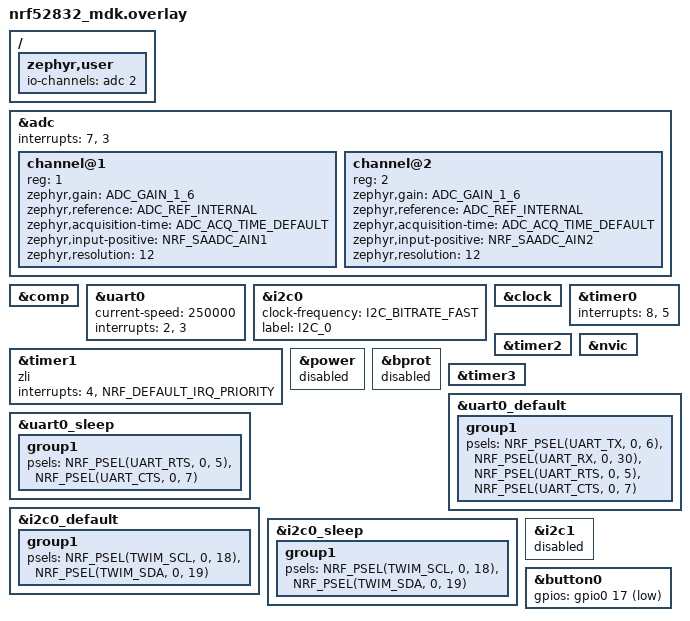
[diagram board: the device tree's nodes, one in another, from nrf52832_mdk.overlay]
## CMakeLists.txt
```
# SPDX-License-Identifier: Apache-2.0

cmake_minimum_required(VERSION 3.20.0)

find_package(Zephyr REQUIRED HINTS $ENV{ZEPHYR_BASE})
project(hello_world)

target_sources(app PRIVATE src/main.c)
target_sources(app PRIVATE src/soft_iic.c)
target_sources(app PRIVATE src/imu_bag.c)
target_sources(app PRIVATE src/timer.c)
target_sources(app PRIVATE src/adc.c)
target_sources(app PRIVATE src/iic_twi.c)
target_sources(app PRIVATE src/uart.c)
target_sources(app PRIVATE src/fft.c)
target_sources(app PRIVATE src/ble.c)
target_sources(app PRIVATE src/ads1015.c)
target_sources(app PRIVATE src/ads1220.c)
target_sources(app PRIVATE src/goertzel.c)
```

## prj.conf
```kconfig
CONFIG_USE_SEGGER_RTT=y
CONFIG_RTT_CONSOLE=y
CONFIG_LED=y
CONFIG_LOG=y
CONFIG_PWM=y
CONFIG_LOG_MODE_IMMEDIATE=y
CONFIG_I2C=y
CONFIG_I2C_NRFX=y
CONFIG_NRFX_TIMER2=y
CONFIG_NRFX_TIMER3=y
CONFIG_ADC=y
CONFIG_UART_ASYNC_API=y
CONFIG_COUNTER=y
CONFIG_DMA=y
CONFIG_SYSCON=y
CONFIG_SERIAL=y
CONFIG_UART_INTERRUPT_DRIVEN=y

CONFIG_NRFX_SAADC=y
CONFIG_NRFX_TWI0=y

CONFIG_BT=y
CONFIG_BT_BROADCASTER=y
CONFIG_BT_EXT_ADV=y
CONFIG_BT_EXT_ADV_MAX_ADV_SET=1
CONFIG_BT_DEVICE_NAME="Broadcaster Multiple"


CONFIG_BT_CTLR_ADV_DATA_LEN_MAX=1065
CONFIG_BT_HCI_VS_EVT_USER=y
CONFIG_BT_CTLR_TX_PWR_ANTENNA=-4


CONFIG_CMSIS_DSP=y
CONFIG_CMSIS_DSP_TRANSFORM=y
CONFIG_CMSIS_DSP_TABLES_ARM_COS_F32=y
CONFIG_CMSIS_DSP_TABLES_ARM_SIN_F32=y
CONFIG_CMSIS_DSP_COMPLEXMATH=y
CONFIG_LOG=y

CONFIG_MAIN_STACK_SIZE=4096


CONFIG_CMSIS_NN=y

CONFIG_CMSIS_DSP_CONTROLLER=y
CONFIG_CMSIS_DSP_FILTERING=y
CONFIG_CMSIS_DSP_INTERPOLATION=y
CONFIG_CMSIS_DSP_MATRIX=y
CONFIG_CMSIS_DSP_QUATERNIONMATH=y
CONFIG_CMSIS_DSP_SVM=y
CONFIG_CMSIS_DSP_BAYES=y
CONFIG_CMSIS_DSP_DISTANCE=y
CONFIG_CMSIS_DSP_LOOPUNROLL=y
CONFIG_CMSIS_DSP_ROUNDING=y
CONFIG_CMSIS_DSP_MATRIXCHECK=y
CONFIG_CMSIS_DSP_AUTOVECTORIZE=y

CONFIG_NRFX_SPI2=y


# # nothing here
# # Enable MCUBoot.
# CONFIG_BOOTLOADER_MCUBOOT=y

# # Enable flash operations.
# CONFIG_FLASH=y

# # Enable MCUmgr and dependencies.
# CONFIG_MCUMGR=y
# CONFIG_NET_BUF=y
# CONFIG_ZCBOR=y
# CONFIG_CRC=y
# CONFIG_STREAM_FLASH=y
# CONFIG_FLASH_MAP=y

# # Enable most core commands.
# CONFIG_IMG_MANAGER=y
# CONFIG_MCUMGR_GRP_IMG=y
# CONFIG_MCUMGR_GRP_OS=y

# # Enable the serial mcumgr transport.
# CONFIG_MCUMGR_TRANSPORT_UART=y
# CONFIG_BASE64=y
# CONFIG_CONSOLE=y

# # Disable UART Console and enable the RTT console
# CONFIG_UART_CONSOLE=n
# CONFIG_RTT_CONSOLE=y
# CONFIG_USE_SEGGER_RTT=y

# # Some command handlers require a large stack.
# CONFIG_SYSTEM_WORKQUEUE_STACK_SIZE=4096
```

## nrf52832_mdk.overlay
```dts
// To get started, press Ctrl+Space to bring up the completion menu and view the available nodes.

// You can also use the buttons in the sidebar to perform actions on nodes.
// Actions currently available include:

// * Enabling / disabling the node
// * Adding the bus to a bus
// * Removing the node
// * Connecting ADC channels

// For more help, browse the DeviceTree documentation at https://docs.zephyrproject.org/latest/guides/dts/index.html
// You can also visit the nRF DeviceTree extension documentation at https://nrfconnect.github.io/vscode-nrf-connect/devicetree/nrfdevicetree.html
/ {
	zephyr,user {
		io-channels = <&adc 2>;
	};
};
&adc {
	#address-cells = <1>;
	#size-cells = <0>;
	channel@1 {
		reg = <1>;
		zephyr,gain = "ADC_GAIN_1_6";
		zephyr,reference = "ADC_REF_INTERNAL";
		zephyr,acquisition-time = <ADC_ACQ_TIME_DEFAULT>;
		zephyr,input-positive = <NRF_SAADC_AIN1>; /* P0.03 */
		zephyr,resolution = <12>;
	};
	channel@2 {
		reg = <2>;
		zephyr,gain = "ADC_GAIN_1_6";
		zephyr,reference = "ADC_REF_INTERNAL";
		zephyr,acquisition-time = <ADC_ACQ_TIME_DEFAULT>;
		zephyr,input-positive = <NRF_SAADC_AIN2>; /* P0.04 */
		zephyr,resolution = <12>;
	};

	status = "okay";

	interrupts = <7>, <3>;
};
&comp {
	status = "okay";
};
&uart0 {
	current-speed = <250000>;
	interrupts = <2>, <3>;
};

&i2c0 {
	clock-frequency = <I2C_BITRATE_FAST>;
	label = "I2C_0";
	status = "okay";
};

&clock {
	status = "okay";
};

&timer0 {
	status = "okay";
	interrupts = <8>, <5>;
};

&timer1 {
	status = "okay";
	zli;
	interrupts = <4>, <NRF_DEFAULT_IRQ_PRIORITY>;
};

&timer2 {
	status = "okay";
};

&nvic {
	status = "okay";
};

&power {
	status = "disabled";
};

&bprot {
	status = "disabled";
};

&timer3 {
	status = "okay";
};

&uart0_default {
	group1 {
		psels = <NRF_PSEL(UART_TX, 0, 6)>,
				<NRF_PSEL(UART_RX, 0, 30)>,
				<NRF_PSEL(UART_RTS, 0, 5)>,
				<NRF_PSEL(UART_CTS, 0, 7)>;
	};
};

&uart0_sleep {
	group1 {
		psels = <NRF_PSEL(UART_RTS, 0, 5)>, <NRF_PSEL(UART_CTS, 0, 7)>;
	};
};
/delete-node/ &{/pin-controller/i2c1_default/group1/};
/delete-node/ &{/pin-controller/i2c1_sleep/group1/};
/delete-node/ &{/pin-controller/i2c0_default/group1/};
/delete-node/ &{/pin-controller/i2c0_sleep/group1/};

&i2c0_default {
	group1 {
		psels = <NRF_PSEL(TWIM_SCL, 0, 18)>, <NRF_PSEL(TWIM_SDA, 0, 19)>;
	};
};

&i2c0_sleep {
	group1 {
		psels = <NRF_PSEL(TWIM_SCL, 0, 18)>, <NRF_PSEL(TWIM_SDA, 0, 19)>;
	};
};

&i2c1 {
	status = "disabled";
};

&button0 {
	gpios = <&gpio0 17 (GPIO_ACTIVE_LOW | GPIO_PULL_UP)>;
};
```

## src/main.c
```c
// /*
//  * Copyright (c) 2012-2014 Wind River Systems, Inc.
//  *
//  * SPDX-License-Identifier: Apache-2.0
//  */
#include "imu_bag.h"
#include "timer.h"
#include "adc.h"
#include "iic_twi.h"
#include "icm_42688.h"
#include "uart.h"
#include <stdio.h>
#include "zephyr/logging/log.h"
#include "nrfx_saadc.h"
#include <zephyr/kernel.h>
#include "nrfx_twi.h"
#include "nrfx_twim.h"
#include "nrfx_gpiote.h"
#include <zephyr/irq.h>
#include "ads1015.h"
#include "ads1220.h"
#include "mymacros.h"
#include "hal/nrf_gpio.h"



//定义一个Gain control 0.31
#define GC NRF_GPIO_PIN_MAP(0, 31) 
// // 定义一个用于读取消息队列的线程堆栈空间
// #define STACK_SIZE 1024
// #define PRIORITY 5
// // 读取线程的栈空间
// K_THREAD_STACK_DEFINE(read_thread_stack, STACK_SIZE);
// // 定义一个线程数据结构
// struct k_thread read_thread_data;
extern struct k_msgq uart_msgq;
char tx_buf[MSG_SIZE];
//尝试使用消息队列
K_MSGQ_DEFINE(uart_msgq2, sizeof(char *), 5, 4); // 队列大小为10，消息长度为指针大小
K_MSGQ_DEFINE(uart_msgq3, sizeof(char *), 3, 4); // 队列大小为10，消息长度为指针大小，存储imu的数据
void get_MSGQ(void)
{
	//用于将数据获取队列并进行输出
	char *msg;
	while(k_msgq_get(&uart_msgq2,&msg,K_NO_WAIT)==0)
	{
		print_uart(msg);
	}
	//进行双消息队列的存储
	while(k_msgq_get(&uart_msgq3,&msg,K_NO_WAIT)==0)
	{
		print_uart(msg);
	}
	// //继续读取中断返回的数
	// while(k_msgq_get(&uart_msgq,&tx_buf,K_NO_WAIT)==0)
	// {
	// 	print_uart(tx_buf);
	// }
}
#define TWI_INSTANCE_ID     0
#define TWI_SCL_PIN         NRF_GPIO_PIN_MAP(0, 18)
#define TWI_SDA_PIN			NRF_GPIO_PIN_MAP(0, 19)
// #define TWI_SCL_PIN         NRF_GPIO_PIN_MAP(0, 27)
// #define TWI_SDA_PIN			NRF_GPIO_PIN_MAP(0, 26)
//定义一个发送完成的变量
bool twi_done=true;
// 定义 TWI 实例结构体
nrfx_twi_t m_twi = NRFX_TWI_INSTANCE(TWI_INSTANCE_ID);
// void twi_handler(nrfx_twi_evt_t const * p_event, void * p_context) 
// {
// 	switch (p_event->type) {
// 		case NRFX_TWI_EVT_DONE:
// 			/* Transfer completed */
// 			twi_done=true;
// 			break;
// 		case NRFX_TWI_EVT_ADDRESS_NACK:
// 			/* NACK received after sending the address */
// 			printk("address nack");
// 			break;
// 		case NRFX_TWI_EVT_DATA_NACK:
// 			/* NACK received after sending a data byte */
// 			printk("data nack");
// 			break;
// 		default:
// 			break;
// 	}
// }
// 初始化 TWI
void twi_init(void)
{
	nrfx_err_t err_code;
    // 配置 TWI
    const nrfx_twi_config_t twi_config = {
        .scl = TWI_SCL_PIN,
        .sda = TWI_SDA_PIN,
        .frequency = NRF_TWI_FREQ_400K,
        .interrupt_priority = 4,
        .hold_bus_uninit = false,
    };
    err_code = nrfx_twi_init(&m_twi, &twi_config, NULL, NULL);
	// IRQ_DIRECT_CONNECT(NRFX_IRQ_NUMBER_GET(NRF_TWI_INST_GET(0)), IRQ_PRIO_LOWEST,
    //                    NRFX_TWI_INST_HANDLER_GET(0), 0);
	// irq_enable(NRFX_IRQ_NUMBER_GET(NRF_TWI_INST_GET(0)));
	// printk("IRQ_PRIO_LOWEST:%d\n",IRQ_PRIO_LOWEST);
	// printk("NRFX_IRQ_NUMBER_GET(NRF_TWI_INST_GET(0)):%d\n",	NRFX_IRQ_NUMBER_GET(NRF_TWI_INST_GET(0)));
	// printk("BIT:%d\n",	 (_IRQ_PRIO_OFFSET));
	// printk("BIT:%d\n",	 twi_config.interrupt_priority);
    // 使能 TWI
    nrfx_twi_enable(&m_twi);
	printk("this is a twi ok");
}

//定义IIC的设备名称
// struct device *i2c_dev;
// #define I2C_DEV_NAME "I2C_0"
//用于进行flag的调用
int flag =0;
//存储一定的AD进而来进行在一定下进行输送
int pd[1000];
int pd2[1000];
//存储一定的imu进行来输送
int imu_count=0;
//用于imu的数据发送
// int count_imu =0;
// int imu_flag =0;
//这里是0.5秒的计时器
int count =1;
int b = 0;
int c = 1;
int imu_flag =0;

//以下是大的时间戳 0.5秒计时一次 0-65536
u_int16_t big_time = 0;
//MovingFlag 与beacondeviceType
uint8_t Mov_type = 0; 
//Moving flag 0为不动 1为动
uint8_t Moving_flag = 0;
//标志不同类型
uint8_t beacon_type = 0;
//标志接受端的电池容量
uint8_t voltage = 0;
//标志接收端的imu的时间戳
int small_time = 0; 

//以下是nrf库的adc采样
LOG_MODULE_REGISTER(adc, LOG_LEVEL_DBG);

#define CHANNEL_COUNT 1

static nrfx_saadc_channel_t single_channel = NRFX_SAADC_DEFAULT_CHANNEL_SE(NRF_SAADC_INPUT_AIN2, 0);
static nrf_saadc_value_t buffer[CHANNEL_COUNT];

void Bsp_HFCLK_Init_Extern()
{
    NRF_CLOCK->EVENTS_HFCLKSTARTED = 0;
    NRF_CLOCK->TASKS_HFCLKSTART = 1;

    while (NRF_CLOCK->EVENTS_HFCLKSTARTED == 0)
    {
        // Do nothing.
    }
}

int adc_init2(void)
{
	Bsp_HFCLK_Init_Extern();
	nrfx_err_t err;
	//初始化 输入初始化的中断优秀级
	err = nrfx_saadc_init(NRFX_SAADC_DEFAULT_CONFIG_IRQ_PRIORITY);
	//配置通道的属性
	single_channel.channel_config.gain = NRF_SAADC_GAIN1_4;
	//显示通道的采样时间间隔
	LOG_INF("TIME=%d\r\n",single_channel.channel_config.acq_time);
	//nrfx_saadc_channel_config完成通道的配置
	err = nrfx_saadc_channel_config(&single_channel);
	//nrfx_saadc_channels_configured_get();记录了当前配置的通道配置情况
	uint32_t channels_mask = nrfx_saadc_channels_configured_get();
	LOG_INF("ADC channels mask: %d\n", channels_mask);
	//设置通道分辨率为12bit，不使用过采样，事件回调
	err = nrfx_saadc_simple_mode_set(channels_mask, NRF_SAADC_RESOLUTION_12BIT, NRF_SAADC_OVERSAMPLE_DISABLED, NULL);
	//在开始 SAADC 转换之前，您需要调用此函数来设置一个缓冲区，SAADC 将把采样数据存储到这个缓冲区中。
	err = nrfx_saadc_buffer_set(buffer, CHANNEL_COUNT);
}

int adc_value_get(void)
{
	nrfx_err_t err;
	//重新补充一下
	Bsp_HFCLK_Init_Extern();
	//nrfx_saadc_offset_calibrate(NULL);校准ADC的偏移量，这里不使用回调函数。
	err = nrfx_saadc_offset_calibrate(NULL);
	//nrfx_saadc_mode_trigger();开始采集数据。
	err = nrfx_saadc_mode_trigger();
	return buffer[0];
}
//转换成电压
int adc_to_voltage(int adc_value)
{
	return (adc_value * 3600) / 4096;
}

int main(void)
{
	// //用于计数
	// int count=0;
	// //用于存储格式化字符串
	// char str[200];
	// //字符指针
	char *P;
	int i=0,offset=0;
	//进行GAIN CONTROL 
	// nrf_gpio_cfg_output(GC);
	// nrf_gpio_pin_set(GC);

	// //硬件IIC zephry库的
	// i2c_dev = device_get_binding(I2C_DEV_NAME);
	// if(!i2c_dev)
	// {
	// 	printk("Failed\n");
	// 	return 0;
	// }else{
	// 	printk("SUCCESS\n");
	// }
	// int err = i2c_configure(i2c_dev, I2C_SPEED_SET(I2C_SPEED_FAST));
    // if (err) {
    //     printk("Failed to configure I2C device: %d\n", err);
    //     return 0;
    // }
    // printk("I2C device configured successfully\n");
	//iic nrf库
	twi_init();
	// 进行imu与bag的初始化
	imu_bag_init();
	// 进行adc初始化
	// adc_init();
	// adc_init2();
	//进行串口初始化
	uart_init_slef();
	// printf("AAA");
	//开始spi的初始化
	if(AD_1220)
	{
 	ads_1015_spi_init();
	//开ads1220的初始化配置
	ads_begin();
	//开始转换
	Start_Conv();
	}
	if(BLE_OK)
	{
	bt_disable();
	broadcaster_multiple();
	}
	//进行定时器初始化 2k采样率 
 	timer1_init_enable(); 
	// //进行定时器初始化 20hz
	timer2_init_enable();

	while (1)
	{
			if(flag)
			{
			//进行FFT处理
			fft();
			//进行一个校准确保是10imu数据
			//然后复位
			imu_flag=0;
			if(BLE_OK)
			{
			ble_data_update();
			}
			//清零
			flag=0;
			// }
		}else{
			//必须加否则会被优化
			get_MSGQ();
			c=1;
		}
	}
}
```

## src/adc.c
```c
/*
 * Copyright (c) 2020 Libre Solar Technologies GmbH
 *
 * SPDX-License-Identifier: Apache-2.0
 */
#include "adc.h"




/* Data of ADC io-channels specified in devicetree. */
static const struct adc_dt_spec adc_channels[] = {
    DT_FOREACH_PROP_ELEM(DT_PATH(zephyr_user), io_channels,
                         DT_SPEC_AND_COMMA)};
static int err;
// static uint32_t count = 0;
static uint16_t buf;
static struct adc_sequence sequence = {
    .buffer = &buf,
    /* buffer size in bytes, not number of samples */
    .buffer_size = sizeof(buf),
};
/**
 * @brief        adc初始化配置
 */
int adc_init(void)
{
    Bsp_HFCLK_Init_Extern();
    /* Configure channels individually prior to sampling. */
    for (size_t i = 0U; i < ARRAY_SIZE(adc_channels); i++)
    {
        if (!adc_is_ready_dt(&adc_channels[i]))
        {
            printk("ADC controller device %s not ready\n", adc_channels[i].dev->name);
            return 0;
        }

        err = adc_channel_setup_dt(&adc_channels[i]);
        if (err < 0)
        {
            printk("Could not setup channel #%d (%d)\n", i, err);
            return 0;
        }
        (void)adc_sequence_init_dt(&adc_channels[i], &sequence);
    }
    return 1;
}
/**
 * @brief        adc读取数据处理
 */
void adc_read_data(void)
{
	//用于存储格式化字符串
	char str[6];
	//字符指针
	char *ptr;

        // printk("ADC reading[%u]:\n", count++);
        for (size_t i = 0U; i < ARRAY_SIZE(adc_channels); i++)
        {
            int32_t val_mv;

            // printk("- %s, channel %d: ",
            //        adc_channels[i].dev->name,
            //        adc_channels[i].channel_id);
            (void)adc_sequence_init_dt(&adc_channels[i], &sequence);
            err = adc_read(adc_channels[i].dev, &sequence);
            if (err < 0)
            {
                printk("Could not read (%d)\n", err);
                continue;
            }
            /*
             * If using differential mode, the 16 bit value
             * in the ADC sample buffer should be a signed 2's
             * complement value.
             */
            if (adc_channels[i].channel_cfg.differential)
            {
                val_mv = (int32_t)((int16_t)buf);
            }
            else
            {
                val_mv = (int32_t)buf;
            }
            // printk("ADC%\n" PRId32, val_mv);
            // printk("%d,", val_mv);
            //用来判断是哪个通道的
            // if(adc_channels[i].channel_id==1)
            // {
            //     //将整数格式化成指针
            //     sprintf(str,"A:%d,",val_mv);
            //     ptr =str;
            //     print_uart(ptr);
            // }else{
            //     //将整数格式化成指针
            //     sprintf(str,"B:%d,",val_mv);
            //     ptr =str;
            //     print_uart(ptr);               
            // }
                //将整数格式化成指针
                sprintf(str,"%d,",val_mv);
                ptr =str;
                print_uart(ptr);


            //下列代码是将ADC原始值变换为mV
            // err = adc_raw_to_millivolts_dt(&adc_channels[i],
            //                                &val_mv);
            // /* conversion to mV may not be supported, skip if not */
            // if (err < 0)
            // {
            //     printk(" (value in mV not available)\n");
            // }
            // else
            // {
            //     printk(" = %" PRId32 " mV\n", val_mv);
            // }
        }
}
```

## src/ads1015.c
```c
#include "ads1015.h"

// //这里就是直接IIC的读取一个字节
// static uint8_t i2cread(void) {
// }
// //这里就是直接IIC的写一个字节
// static void i2cwrite(uint8_t x) {
// }

// //这里就是IIC对特定的地址与特定的寄存器进行写16位的数据
// static void writeRegister(uint8_t i2cAddress, uint8_t reg, uint16_t value) {
// }

// //这里就是IIC对特定的地址与特定的寄存器进行读16位的数据
// static uint16_t readRegister(uint8_t i2cAddress, uint8_t reg) {
// }

/**************************************************************************/
/*!
    @brief  Gets a single-ended ADC reading from the specified channel
*/
/**************************************************************************/
void Ads1015init(uint8_t channel) {
  if (channel > 3)
  {
    return 0;
  }
  
  // Start with default values
  uint16_t config = ADS1015_REG_CONFIG_CQUE_NONE    | // Disable the comparator (default val)
                    ADS1015_REG_CONFIG_CLAT_NONLAT  | // Non-latching (default val)
                    ADS1015_REG_CONFIG_CPOL_ACTVLOW | // Alert/Rdy active low   (default val)
                    ADS1015_REG_CONFIG_CMODE_TRAD   | // Traditional comparator (default val)
                    ADS1015_REG_CONFIG_DR_3300SPS   | // 1600 samples per second (default)
                    ADS1015_REG_CONFIG_MODE_SINGLE;   // Single-shot mode (default)

  // Set PGA/voltage range
  config |= ADS1015_REG_CONFIG_PGA_4_096V;

  // Set single-ended input channel
  switch (channel)
  {
    case (0):
      config |= ADS1015_REG_CONFIG_MUX_SINGLE_0;
      break;
    case (1):
      config |= ADS1015_REG_CONFIG_MUX_SINGLE_1;
      break;
    case (2):
      config |= ADS1015_REG_CONFIG_MUX_SINGLE_2;
      break;
    case (3):
      config |= ADS1015_REG_CONFIG_MUX_SINGLE_3;
      break;
  }

  // Set 'start single-conversion' bit
  config |= ADS1015_REG_CONFIG_OS_SINGLE;

  // Write config register to the ADC（这个是16位的）
  writeRegister(ADS1015_ADDRESS, ADS1015_REG_POINTER_CONFIG, config);

}

uint16_t Ads1015read(void){
  // Read the conversion results 
   // 读 config register to the ADC（这个是16位的）
  // Shift 12-bit results right 4 bits for the ADS1015
  return readRegister(ADS1015_ADDRESS, ADS1015_REG_POINTER_CONVERT) >> 4;  
}
```

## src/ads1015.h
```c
#ifndef _ADS1015_H
#define _ADS1015_H

#include <stdio.h>
#include <stdint.h>

#include <zephyr/kernel.h>
#include <zephyr/drivers/gpio.h>
#include <nrfx_gpiote.h>
#include "soft_iic.h"
#include "icm_42688.h"
#include "lis3dml.h"
#include "uart.h"

/*=========================================================================
    I2C ADDRESS/BITS
    -----------------------------------------------------------------------*/
    #define ADS1015_ADDRESS                 (0x48)    // 1001 000 (ADDR = GND)
/*=========================================================================*/

/*=========================================================================
    CONVERSION DELAY (in mS)
    -----------------------------------------------------------------------*/
    #define ADS1015_CONVERSIONDELAY         (1)
    #define ADS1115_CONVERSIONDELAY         (15)
/*=========================================================================*/

/*=========================================================================
    POINTER REGISTER
    -----------------------------------------------------------------------*/
    #define ADS1015_REG_POINTER_MASK        (0x03)
    #define ADS1015_REG_POINTER_CONVERT     (0x00)
    #define ADS1015_REG_POINTER_CONFIG      (0x01)
    #define ADS1015_REG_POINTER_LOWTHRESH   (0x02)
    #define ADS1015_REG_POINTER_HITHRESH    (0x03)
/*=========================================================================*/

/*=========================================================================
    CONFIG REGISTER
    -----------------------------------------------------------------------*/
    #define ADS1015_REG_CONFIG_OS_MASK      (0x8000)
    #define ADS1015_REG_CONFIG_OS_SINGLE    (0x8000)  // Write: Set to start a single-conversion
    #define ADS1015_REG_CONFIG_OS_BUSY      (0x0000)  // Read: Bit = 0 when conversion is in progress
    #define ADS1015_REG_CONFIG_OS_NOTBUSY   (0x8000)  // Read: Bit = 1 when device is not performing a conversion

    #define ADS1015_REG_CONFIG_MUX_MASK     (0x7000)
    #define ADS1015_REG_CONFIG_MUX_DIFF_0_1 (0x0000)  // Differential P = AIN0, N = AIN1 (default)
    #define ADS1015_REG_CONFIG_MUX_DIFF_0_3 (0x1000)  // Differential P = AIN0, N = AIN3
    #define ADS1015_REG_CONFIG_MUX_DIFF_1_3 (0x2000)  // Differential P = AIN1, N = AIN3
    #define ADS1015_REG_CONFIG_MUX_DIFF_2_3 (0x3000)  // Differential P = AIN2, N = AIN3
    #define ADS1015_REG_CONFIG_MUX_SINGLE_0 (0x4000)  // Single-ended AIN0
    #define ADS1015_REG_CONFIG_MUX_SINGLE_1 (0x5000)  // Single-ended AIN1
    #define ADS1015_REG_CONFIG_MUX_SINGLE_2 (0x6000)  // Single-ended AIN2
    #define ADS1015_REG_CONFIG_MUX_SINGLE_3 (0x7000)  // Single-ended AIN3

    #define ADS1015_REG_CONFIG_PGA_MASK     (0x0E00)
    #define ADS1015_REG_CONFIG_PGA_6_144V   (0x0000)  // +/-6.144V range = Gain 2/3
    #define ADS1015_REG_CONFIG_PGA_4_096V   (0x0200)  // +/-4.096V range = Gain 1
    #define ADS1015_REG_CONFIG_PGA_2_048V   (0x0400)  // +/-2.048V range = Gain 2 (default)
    #define ADS1015_REG_CONFIG_PGA_1_024V   (0x0600)  // +/-1.024V range = Gain 4
    #define ADS1015_REG_CONFIG_PGA_0_512V   (0x0800)  // +/-0.512V range = Gain 8
    #define ADS1015_REG_CONFIG_PGA_0_256V   (0x0A00)  // +/-0.256V range = Gain 16

    #define ADS1015_REG_CONFIG_MODE_MASK    (0x0100)
    #define ADS1015_REG_CONFIG_MODE_CONTIN  (0x0000)  // Continuous conversion mode
    #define ADS1015_REG_CONFIG_MODE_SINGLE  (0x0100)  // Power-down single-shot mode (default)

    #define ADS1015_REG_CONFIG_DR_MASK      (0x00E0)  
    #define ADS1015_REG_CONFIG_DR_128SPS    (0x0000)  // 128 samples per second
    #define ADS1015_REG_CONFIG_DR_250SPS    (0x0020)  // 250 samples per second
    #define ADS1015_REG_CONFIG_DR_490SPS    (0x0040)  // 490 samples per second
    #define ADS1015_REG_CONFIG_DR_920SPS    (0x0060)  // 920 samples per second
    #define ADS1015_REG_CONFIG_DR_1600SPS   (0x0080)  // 1600 samples per second (default)
    #define ADS1015_REG_CONFIG_DR_2400SPS   (0x00A0)  // 2400 samples per second
    #define ADS1015_REG_CONFIG_DR_3300SPS   (0x00C0)  // 3300 samples per second

    #define ADS1015_REG_CONFIG_CMODE_MASK   (0x0010)
    #define ADS1015_REG_CONFIG_CMODE_TRAD   (0x0000)  // Traditional comparator with hysteresis (default)
    #define ADS1015_REG_CONFIG_CMODE_WINDOW (0x0010)  // Window comparator

    #define ADS1015_REG_CONFIG_CPOL_MASK    (0x0008)
    #define ADS1015_REG_CONFIG_CPOL_ACTVLOW (0x0000)  // ALERT/RDY pin is low when active (default)
    #define ADS1015_REG_CONFIG_CPOL_ACTVHI  (0x0008)  // ALERT/RDY pin is high when active

    #define ADS1015_REG_CONFIG_CLAT_MASK    (0x0004)  // Determines if ALERT/RDY pin latches once asserted
    #define ADS1015_REG_CONFIG_CLAT_NONLAT  (0x0000)  // Non-latching comparator (default)
    #define ADS1015_REG_CONFIG_CLAT_LATCH   (0x0004)  // Latching comparator

    #define ADS1015_REG_CONFIG_CQUE_MASK    (0x0003)
    #define ADS1015_REG_CONFIG_CQUE_1CONV   (0x0000)  // Assert ALERT/RDY after one conversions
    #define ADS1015_REG_CONFIG_CQUE_2CONV   (0x0001)  // Assert ALERT/RDY after two conversions
    #define ADS1015_REG_CONFIG_CQUE_4CONV   (0x0002)  // Assert ALERT/RDY after four conversions
    #define ADS1015_REG_CONFIG_CQUE_NONE    (0x0003)  // Disable the comparator and put ALERT/RDY in high state (default)
/*=========================================================================*/

typedef enum
{
  GAIN_TWOTHIRDS    = ADS1015_REG_CONFIG_PGA_6_144V,
  GAIN_ONE          = ADS1015_REG_CONFIG_PGA_4_096V,
  GAIN_TWO          = ADS1015_REG_CONFIG_PGA_2_048V,
  GAIN_FOUR         = ADS1015_REG_CONFIG_PGA_1_024V,
  GAIN_EIGHT        = ADS1015_REG_CONFIG_PGA_0_512V,
  GAIN_SIXTEEN      = ADS1015_REG_CONFIG_PGA_0_256V
} adsGain_t;

void Ads1015init(uint8_t channel);
uint16_t Ads1015read(void);
#endif
```

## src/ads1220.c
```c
#include "ads1220.h"
//#define BOARD_SENSYTHING ST_1_3
//创建了一个 SPISettings 对象，配置了 SPI 通信的时钟频率为 2 MHz，
//数据传输顺序为最高有效位优先，SPI 模式为模式 1。
//这个设置可以在 SPI 传输开始时使用，以确保主设备和从设备之间的通信参数一致


#ifdef _BV
#undef _BV
#endif

//定义
#define _BV(bit) (1<<(bit))

//spi的初始化
void ads_1015_spi_init(void)
{
        //配置SPI
        nrfx_spi_config_t spi_config = NRFX_SPI_DEFAULT_CONFIG(SPI_SCK_PIN,MOSI_PIN,MISO_PIN,SPI_CS_PIN);
        //根据需求开始更改自己的设置 时钟与数据的高低为都已弄好
        // spi_config.ss_pin = SPI_CS_PIN;
        // spi_config.miso_pin = MISO_PIN;
        // spi_config.mosi_pin = MOSI_PIN;
        // spi_config.sck_pin = SPI_SCK_PIN;
        spi_config.frequency=NRF_SPI_FREQ_8M;
        spi_config.mode = NRF_SPI_MODE_1;
        
        //开始初始化 开始阻塞读写
         nrfx_spi_init(&spi,&spi_config,NULL,NULL);
        // printk("520today%d",a);
}

//用于写一个八位的寄存器
void writeRegister2(uint8_t address, uint8_t value)
{
    //发送与输出的TX与RX的缓冲
    uint8_t spi_tx_buf[2];
    uint8_t spi_rx_buf[2];

    spi_tx_buf[0]=WREG|(address<<2);
    spi_tx_buf[1]=value;
    nrfx_spi_xfer_desc_t  s_w =NRFX_SPI_XFER_TRX(spi_tx_buf,sizeof(spi_tx_buf),NULL,0);
    // nrfx_spi_xfer_desc_t  s_w =NRFX_SPI_XFER_TRX(spi_tx_buf,sizeof(spi_tx_buf),spi_rx_buf,sizeof(spi_rx_buf));
    nrfx_spi_xfer(&spi,&s_w, 0);
}
//用于读一个八位的寄存器
uint8_t readRegister2(uint8_t address)
{
    uint8_t data;
    //发送与输出的TX与RX的缓冲
    uint8_t spi_tx_buf[2];
    uint8_t spi_rx_buf[2];
    spi_tx_buf[0]=RREG|(address<<2);
    spi_tx_buf[1]=0xFF;
    nrfx_spi_xfer_desc_t  s_w =NRFX_SPI_XFER_TRX(spi_tx_buf,sizeof(spi_tx_buf),spi_rx_buf,sizeof(spi_rx_buf));
    nrfx_spi_xfer(&spi,&s_w, 0);
    data =spi_rx_buf[0];
    return data;
}

// ads配置初始化
void ads_begin(void)
{
    //进行重启
    ads1220_Reset();
    printk("aaa");
    //加延时
    k_msleep(50);

    //开始写入配置
    uint8_t m_config_reg0 = 0x80;   //settings: AINP=A0, AINN=GND, Gain 1, PGA enabled
    uint8_t m_config_reg1 = 0xD4;   //settings: DR=2000 SPS, Mode=Trbuo, Conv mode=con shot, Temp Sensor disabled, Current Source off
    uint8_t m_config_reg2 = 0x10;   //settings: Vref internal, 50/60Hz rejection, power open, IDAC off
    uint8_t m_config_reg3 = 0x00;   //settings: IDAC1 disabled, IDAC2 disabled, DRDY pin only

    writeRegister2( CONFIG_REG0_ADDRESS , m_config_reg0);
    writeRegister2( CONFIG_REG1_ADDRESS , m_config_reg1);
    writeRegister2( CONFIG_REG2_ADDRESS , m_config_reg2);
    writeRegister2( CONFIG_REG3_ADDRESS , m_config_reg3);
}
//直接发送一个短的字符
void SPI_Command(uint8_t data_in)
{
    //发送与输出的TX与RX的缓冲
    uint8_t spi_tx_buf[1];
    spi_tx_buf[0]=data_in;
    nrfx_spi_xfer_desc_t  s_w =NRFX_SPI_XFER_TRX(spi_tx_buf,sizeof(spi_tx_buf),NULL,0);
    nrfx_spi_xfer(&spi,&s_w, 0);

}
void ads1220_Reset(void)
{
    SPI_Command(RESET);
}
void Start_Conv(void)
{
    SPI_Command(START);
}

int  Read_Data(void){
    int  result = 0;
    uint8_t spi_tx_buf[1]={0x10};
    uint8_t spi_rx_buf[4]={0};
    nrfx_spi_xfer_desc_t  s_w =NRFX_SPI_XFER_TRX(spi_tx_buf,sizeof(spi_tx_buf),spi_rx_buf,sizeof(spi_rx_buf));
    nrfx_spi_xfer(&spi,&s_w, 0);
    result = spi_rx_buf[1];
    result = (result << 8) | spi_rx_buf[2];
    result = (result << 8) | spi_rx_buf[3];
    // if (spi_rx_buf[0] & (1<<7)) {
    //     result |= 0xFF000000;
    // }

    return result;
}
```

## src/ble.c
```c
#include "ble.h"
#include "timer.h"
/*
 * Datalength is an integer, so BT_MFG_DATA_LEN can not be larger than 255.
 * To ensure that we need to chain PDUs we therefore add manufacturer data
 * twice when chaining is enabled
 */
extern u_int16_t big_time ;
extern int fft_out[6];
extern int fft_index[6];
extern SensorData imu_10_2[10];

static uint8_t mfg_data[BT_MFG_DATA_LEN-18]  = { 0xFF,0xFF,0x01};
// static uint8_t mfg_data1[BT_MFG_DATA_LEN] = { 0xFF, 0xFF,0x11,0x12,0x13,0x14,0x15,0x16,0x17};
// static uint8_t mfg_data2[BT_MFG_DATA_LEN] = { 0xFF, 0xFF,0x03};
// static uint8_t mfg_data3[BT_MFG_DATA_LEN] = { 0xFF, 0xFF,0x04};
static const struct bt_data ad[] = {
	BT_DATA(BT_DATA_MANUFACTURER_DATA, mfg_data, sizeof(mfg_data)),
	// BT_DATA(BT_DATA_MANUFACTURER_DATA, mfg_data1, sizeof(mfg_data1)),
	// BT_DATA(BT_DATA_MANUFACTURER_DATA, mfg_data2, sizeof(mfg_data2)),
	// BT_DATA(BT_DATA_MANUFACTURER_DATA, mfg_data3, sizeof(mfg_data3)),
};
//广播参数实现
static struct bt_le_ext_adv *adv[CONFIG_BT_EXT_ADV_MAX_ADV_SET];
//广播的mac地址
static const bt_addr_le_t fixed_addr = {
    .type = BT_ADDR_LE_PUBLIC,  // 地址类型，使用公共地址
    .a = {
        .val = { 0x01, 0x23, 0x45, 0x67, 0x89, 0xAB }  // 固定的地址
    }
};
struct bt_le_adv_param adv_param = {
			.id = BT_ID_DEFAULT,
			.sid = 0U, /* Supply unique SID when creating advertising set */
			.secondary_max_skip = 0U,
			// .options = (BT_LE_ADV_OPT_EXT_ADV | BT_LE_ADV_OPT_USE_NAME),
			.options = (BT_LE_ADV_OPT_EXT_ADV | BT_LE_ADV_OPT_USE_NAME|BT_LE_ADV_OPT_USE_IDENTITY),
			// .interval_min = 0x0258,
			// .interval_max = 0x0258,
			.interval_min = 0x0020,
			.interval_max = 0x0020,
			.peer = NULL,
};//间隔为50ms
int err;
int broadcaster_multiple(void)
{

	/* Initialize the Bluetooth Subsystem */
	err = bt_enable(NULL);
	if (err) {
		printk("Bluetooth init failed (err %d)\n", err);
		return err;
	}
	//设置蓝牙的mac地址

	//设置广播数据
	mfg_data[235]=0xAF;
	for (int index = 0; index < CONFIG_BT_EXT_ADV_MAX_ADV_SET; index++) {
		/* Use advertising set instance index as SID */
		adv_param.sid = index;
		/* Create a non-connectable non-scannable advertising set */
		err = bt_le_ext_adv_create(&adv_param, NULL, &adv[index]);
		if (err) {
			printk("Failed to create advertising set %d (err %d)\n",
			       index, err);
			return err;
		}
		/* Set extended advertising data */
		err = bt_le_ext_adv_set_data(adv[index], ad, ARRAY_SIZE(ad),
					     NULL, 0);
		if (err) {
			printk("Failed to set advertising data for set %d "
			       "(err %d)\n", index, err);
			return err;
		}
		/* Start extended advertising set */   
		err = bt_le_ext_adv_start(adv[index],BT_LE_EXT_ADV_START_DEFAULT);
		if (err) {
			printk("Failed to start extended advertising set %d "
			       "(err %d)\n", index, err);
			return err;
		}
		printk("Started Extended Advertising Set %d.\n", index);
	}
	return 0;
}
//进行数据的改变
void ble_data_change()
{
	int a=2;	
	int i=0;
	//时间戳的高低位设置
	mfg_data[0+a]=(big_time>>8)&0xFF;
	mfg_data[1+a]=big_time&0xFF;
	//移动标志与设备类型一个字节
	mfg_data[2+a]=0x01;
	//电压一个字节
	mfg_data[3+a]=0xFF;
	//VLP包
	mfg_data[4+a]=(fft_index[0]>>2)&0xFF;
	mfg_data[5+a]=((fft_index[0]&0x03)<<6)|((fft_out[0]>>8)&0x3F);	
	mfg_data[6+a]=fft_out[0]&0xFF;

	mfg_data[7+a]=(fft_index[1]>>2)&0xFF;
	mfg_data[8+a]=((fft_index[1]&0x03)<<6)|((fft_out[1]>>8)&0x3F);	
	mfg_data[9+a]=fft_out[1]&0xFF;

	mfg_data[10+a]=(fft_index[2]>>2)&0xFF;
	mfg_data[11+a]=((fft_index[2]&0x03)<<6)|((fft_out[2]>>8)&0x3F);	
	mfg_data[12+a]=fft_out[2]&0xFF;

	mfg_data[13+a]=(fft_index[3]>>2)&0xFF;
	mfg_data[14+a]=((fft_index[3]&0x03)<<6)|((fft_out[3]>>8)&0x3F);	
	mfg_data[15+a]=fft_out[3]&0xFF;

	mfg_data[16+a]=(fft_index[4]>>2)&0xFF;
	mfg_data[17+a]=((fft_index[4]&0x03)<<6)|((fft_out[4]>>8)&0x3F);	
	mfg_data[18+a]=fft_out[4]&0xFF;

	mfg_data[19+a]=(fft_index[5]>>2)&0xFF;
	mfg_data[20+a]=((fft_index[5]&0x03)<<6)|((fft_out[5]>>8)&0x3F);	
	mfg_data[21+a]=fft_out[5]&0xFF;
	
	//vlp包imu 		
	//先进行imu时间戳的对齐10bit 四个为一组
	mfg_data[22+a]=(imu_10_2[0].time>>2)&0xFF;
	//2+6
	mfg_data[23+a]=((imu_10_2[0].time&0x03)<<6)|((imu_10_2[1].time>>4)&0x3F);
	//4+4	
	mfg_data[24+a]=((imu_10_2[1].time&0x0F)<<4)|((imu_10_2[2].time>>6)&0x0F);
	//6+2
	mfg_data[25+a]=((imu_10_2[2].time&0x3F)<<2)|((imu_10_2[3].time>>8)&0x03);
	mfg_data[26+a]=imu_10_2[3].time&0xFF;

	// //第二组时间戳
	mfg_data[27+a]=(imu_10_2[4].time>>2)&0xFF;
	//2+6
	mfg_data[28+a]=((imu_10_2[4].time&0x03)<<6)|((imu_10_2[5].time>>4)&0x3F);
	//4+4	
	mfg_data[29+a]=((imu_10_2[5].time&0x0F)<<4)|((imu_10_2[6].time>>6)&0x0F);
	//6+2
	mfg_data[30+a]=((imu_10_2[6].time&0x3F)<<2)|((imu_10_2[7].time>>8)&0x03);
	mfg_data[31+a]=imu_10_2[7].time&0xFF;

	//第三组时间戳
	mfg_data[32+a]=(imu_10_2[8].time>>2)&0xFF;
	//2+6
	mfg_data[33+a]=((imu_10_2[8].time&0x03)<<6)|((imu_10_2[9].time>>4)&0x3F);
	//4+4	
	mfg_data[34+a]=((imu_10_2[9].time&0x0F)<<4)|0x00;
	a=a+1;
	// //在进行imu的数据传递 xyz
	for(i=0;i<10;i++)
	{
		//acc x
		mfg_data[34+a]=imu_10_2[i].icm[0];
		mfg_data[35+a]=imu_10_2[i].icm[1];
		//acc y
		mfg_data[36+a]=imu_10_2[i].icm[2];
		mfg_data[37+a]=imu_10_2[i].icm[3];
		//acc z
		mfg_data[38+a]=imu_10_2[i].icm[4];
		mfg_data[39+a]=imu_10_2[i].icm[5];

		a=a+6;

		//gyro x
		mfg_data[34+a]=imu_10_2[i].icm[6];
		mfg_data[35+a]=imu_10_2[i].icm[7];
		//gyro y
		mfg_data[36+a]=imu_10_2[i].icm[8];
		mfg_data[37+a]=imu_10_2[i].icm[9];
		//gyro z
		mfg_data[38+a]=imu_10_2[i].icm[10];
		mfg_data[39+a]=imu_10_2[i].icm[11];

		a=a+6;
		//mag x
		mfg_data[34+a]=imu_10_2[i].lis[1];
		mfg_data[35+a]=imu_10_2[i].lis[0];
		//mag y
		mfg_data[36+a]=imu_10_2[i].lis[3];
		mfg_data[37+a]=imu_10_2[i].lis[2];
		//mag z
		mfg_data[38+a]=imu_10_2[i].lis[5];
		mfg_data[39+a]=imu_10_2[i].lis[4];
       
	   a=a+6;
	}


// 在进行imu的数据传递 xyz
// a=a+1;
// 	for(i=0;i<10;i++)
// 	{
// 		//acc x
// 		mfg_data[34+a]=0x11;
// 		mfg_data[35+a]=0x22;
// 		//acc y
// 		mfg_data[36+a]=0x33;
// 		mfg_data[37+a]=0x44;
// 		//acc z
// 		mfg_data[38+a]=0x55;
// 		mfg_data[39+a]=0x66;

// 		a=a+6;

// 		//gyro x
// 		mfg_data[34+a]=0x77;
// 		mfg_data[35+a]=0x88;
// 		//gyro y
// 		mfg_data[36+a]=0x99;
// 		mfg_data[37+a]=0xAA;
// 		//gyro z
// 		mfg_data[38+a]=0xBB;
// 		mfg_data[39+a]=0xCC;

// 		a=a+6;
// 		//mag x
// 		mfg_data[34+a]=0xDD;
// 		mfg_data[35+a]=0x11;
// 		//mag y
// 		mfg_data[36+a]=0x22;
// 		mfg_data[37+a]=0x33;
// 		//mag z
// 		mfg_data[38+a]=0x44;
// 		mfg_data[39+a]=0x55;
       
// 	   a=a+6;
// 	}


}
//进行更新数据
void ble_data_update()
{
	//先暂停广播
	bt_le_ext_adv_stop(adv[0]);
	//开始更新广播
	ble_data_change();
	//重新填写广播
	bt_le_ext_adv_set_data(adv[0], ad, ARRAY_SIZE(ad),NULL, 0);
	//重新开启广播
	bt_le_ext_adv_start(adv[0],BT_LE_EXT_ADV_START_DEFAULT);
}
```

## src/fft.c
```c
#include "fft.h"
#include "goertzel.h"
//定义相关的频率的点位(在点位范围内上下加减2) 频率为213,437,589,777,943,985
// int fre_num[6]={218-2,447-2,603-2,795-2,965-2,1008-2};
//[896,854,646,604,958,292,354,396];2048
// int fre_num[8]={918-5,875-5,662-5,619-5,981-5,300-5,363-5,406-5};
//[896,854,646,604,958,292,354,396];1024
// int fre_num[8]={458-2,437-2,330-2,309-2,490-2,149-2,181-2,202-2};
// //新频率
// int fre_num[8]={106-2, 181-2, 257-2, 338-2, 347-2, 422-2,463-2,472-2};

//新频率 12盏 208, 282, 320, 354, 416, 502, 662, 678, 826, 906, 922, 992
// int fre_num[12]={106-2, 144-2,163-2,181-2,213-2, 257-2, 338-2, 347-2, 422-2,463-2,472-2,508-2};
//G算法
int fre_num[12]={208, 282, 320, 354, 416, 502, 662, 678, 826, 906, 922, 992};
arm_cfft_instance_f32 scfft;
extern int pd2[1000];
extern u_int16_t big_time ;
/* FFT信号数组，包含实部和虚部 */
float fft_input_buf[FFT_LENGTH * 2];
/* FFT输出结果数组，幅度输出 */
float fft_output_mag_buf[FFT_LENGTH];
/*FFT最大的六个值以及输出*/
int fft_out[6];
int fft_index[6];
//用于调试
char str_a[100];
//字符指针
char *P_a;
int  offset_a=0;
//用于调试    
char str_a1[100];
//字符指针
char *P_a1;
int  offset_a1=0;
static  int FFT_first=0;
//存储一个数组用于保存1000个数据
int pd3[1000];
//存储一个48点的值
int pd4[48]={0};
// 交换两个整数的值
void swap(int* a, int* b) {
    int temp = *a;
    *a = *b;
    *b = temp;
}

// 选择前 6 大的元素及其位置
void find_top_6(int values[], int positions[], int size) {
    // 遍历数组，找到前 8 大的元素
    for (int i = 0; i < 6; i++) {
        int max_idx = i;  // 假设当前元素是最大的
        for (int j = i + 1; j < size; j++) {
            if (values[j] > values[max_idx]) {
                max_idx = j;
            }
        }
        // 交换当前最大值到第 i 个位置
        if (max_idx != i) {
            swap(&values[i], &values[max_idx]);
            swap(&positions[i], &positions[max_idx]);
        }
    }
}


// int fft(void)
// {
// 	uint32_t maxIndex;
//     float32_t maxValue;
// 	//用于存储临时的值
// 	int temp_fft_out[12];
// 	int temp_fft_index[12];
// 	//求一下直流均值
// 	int dc_val=0;
// 	arm_mean_f32(pd2,1000,&dc_val);
//     /* ===================fft部分=================== */
// 	/* 初始化scfft结构体，设定FFT相关参数*/
// 	arm_cfft_init_f32(&scfft, FFT_LENGTH);
// 	int i =0;
// 	/* 生成信号序列 */
// 	//1024点
// 	if(FFT_first==0)
// 	{
// 		for ( i = 0; i < FFT_LENGTH; i++)
// 		{
// 			//实部进行PD数据的赋值 只保留后面48个
// 			if(i<24)
// 			{
// 			fft_input_buf[2 * i] = pd2[i];
// 			//存储只保留后面48个
// 			pd4[i]=pd2[i+976];
// 			}else{
// 			fft_input_buf[2 * i] = 0;
// 			}
// 			/* 虚部 */
// 			fft_input_buf[2 * i + 1] = 0;
// 		}
// 		FFT_first=1;
// 	}else{
// 		for ( i = 0; i < FFT_LENGTH; i++)
// 		{
// 			//实部进行PD数据的赋值
// 			if(i<24)
// 			{
// 			fft_input_buf[2 * i] = pd4[i]-dc_val;
// 			//存储代码为后续做准备
// 			pd4[i]=pd2[i+976];
// 			}else{
// 			fft_input_buf[2 * i] = pd2[i-24]-dc_val;
// 			}
			
// 			/* 虚部 */
// 			fft_input_buf[2 * i + 1] = 0;
// 		}		
// 	}
// 	//输出i
// 	// printk("i:%d\n",i);
// 	/* FFT计算 */
// 	arm_cfft_f32(&scfft, fft_input_buf, 0, 1);
// 	 /* 运算结果求幅值 */
// 	arm_cmplx_mag_f32(fft_input_buf, fft_output_mag_buf, FFT_LENGTH);
// 	// printk("i:%d\n",i+1);

// 	//以下是输出的FFT的值
// 	if(FFT_UART_Display)
// 	{
// 		for (int i = 0; i < FFT_LENGTH; i++)
// 		{
// 			printk("%d.%d, ", (uint16_t)(fft_output_mag_buf[i]), (uint16_t)((fft_output_mag_buf[i] - (uint16_t)(fft_output_mag_buf[i])) * 100.0));
// 			// if ((i + 1) % 32 == 0)
// 			// {
// 			// 	printk("\n");
// 			// }
// 		}
// 		// printk("fft end\n");
// 	}



// 	//for 循环 在对应频率 取得最大的数值
// 	for(i=0;i<12;i++)
// 	{
// 		//找寻最大值
//     	arm_max_f32(&fft_output_mag_buf[fre_num[i]], 5, &maxValue, &maxIndex);
// 		//将最大值存入数组 记录数值,并保留两位小数
// 		// fft_out[i]=(int)(maxValue*2/1000*100);
// 		temp_fft_out[i]=(int)(maxValue*2/1000*100);
// 		temp_fft_index[i]=(int)maxIndex+fre_num[i];
// 	}
// 	//再冲12个里面选取最大的数值
// 	// 查找前 12 大的元素
//     find_top_6(temp_fft_out, temp_fft_index, 12);
// 	//进行赋值
// 	for (int i = 0; i < 6; i++) {
// 		fft_out[i]=temp_fft_out[i];
// 		fft_index[i]=temp_fft_index[i];
//     }
// 	//串口检验FFT的大小
// 	if(fft_UART_Display)
// 	{
// 		for(i=0;i<6;i++)
// 		{
// 			offset_a1 += sprintf(str_a1 + offset_a1, "index %d:%d,", fft_index[i],fft_out[i]); 
// 		}
// 		// P_a=str_a;
// 		// print_uart(P_a);
// 		// offset_a=0;
// 		//串口输出原始值
// 		offset_a1+=sprintf(str_a1 + offset_a1, "T%d\n",big_time); 
// 		P_a1=str_a1;
// 		offset_a1=0;
// 		if(k_msgq_put(&uart_msgq2,&P_a1,K_NO_WAIT)!=0)
// 		{
// 			//丢弃
// 			printk("too much\n");
// 		}
// 		P_a1=NULL;
// 		// print_uart(P_a);
// 		// print_uart("\n");
// 	}
// 	//输出ADC值
// 	if(fft_pd_uart)
// 	{
// 		for(int j=1;j<21;j++)
// 		{
// 			for(i=1;i<51;i++)
// 			{
// 			offset_a+=sprintf(str_a + offset_a,"%d,",pd2[i*j-1]); 
// 			}
// 			if(j==20){
// 			offset_a+=sprintf(str_a + offset_a, "\n"); 
// 			P_a=str_a;
// 			offset_a=0;
// 			}else{
// 				P_a=str_a;
// 				offset_a=0;
// 			}
// 			if(k_msgq_put(&uart_msgq2,&P_a,K_NO_WAIT)!=0)
// 			{
// 			//丢弃
// 			printk("too much\n");
// 			}
// 			P_a=NULL;
// 		}
// 	}
// 	return 0;
// }

int fft(void)
{
	uint32_t maxIndex;
    float32_t maxValue;
	//用于存储临时的值
	int temp_fft_out[12];
	int temp_fft_index[12];
	//求一下直流均值
	int dc_val=0;
	//执行九次

    /* ===================fft部分=================== */

	//再冲12个里面选取最大的数值
	// printk("pd2:%d\n",pd2[0]);
	// printk("pd2:%d\n",pd2[1]);
	// printk("pd2:%d\n",pd2[2]);
	// printk("pd2:%d\n",pd2[3]);
	// printk("pd2:%d\n",pd2[4]);
	// printk("pd2:%d\n",pd2[5]);
	
	// 查找前 12 大的元素
	for(int i=0;i<12;i++)
	{
		temp_fft_out[i]=2*sqrt(goertzel(pd2, 1000, 2000, fre_num[i]))/1000*100;
		// temp_fft_out[i]=goertzel(pd2, 1000, 2000, fre_num[i]);
		temp_fft_index[i]=fre_num[i];
		// printk("index %d:%d,",temp_fft_index[i],temp_fft_out[i]);
	}

    find_top_6(temp_fft_out, temp_fft_index, 12);
	//进行赋值
	for (int i = 0; i < 6; i++) {
		fft_out[i]=temp_fft_out[i];
		fft_index[i]=temp_fft_index[i];
    }
	//串口检验FFT的大小
	if(fft_UART_Display)
	{
		// offset_a1 += sprintf(str_a1 + offset_a1, "\n"); 
		for(int i=0;i<6;i++)
		{
			offset_a1 += sprintf(str_a1 + offset_a1, "index %d:%d,", fft_index[i],fft_out[i]); 
		}
		// P_a=str_a;
		// print_uart(P_a);
		// offset_a=0;
		//串口输出原始值
		offset_a1+=sprintf(str_a1 + offset_a1, "T%d\n",big_time); 
		P_a1=str_a1;
		offset_a1=0;
		if(k_msgq_put(&uart_msgq2,&P_a1,K_NO_WAIT)!=0)
		{
			//丢弃
			printk("too much\n");
		}
		P_a1=NULL;
		// print_uart(P_a);
		// print_uart("\n");
	}
	//输出ADC值
	if(fft_pd_uart)
	{
		for(int j=1;j<21;j++)
		{
			for(int i=1;i<51;i++)
			{
			offset_a+=sprintf(str_a + offset_a,"%d,",pd2[i*j-1]); 
			}
			if(j==20){
			offset_a+=sprintf(str_a + offset_a, "\n"); 
			P_a=str_a;
			offset_a=0;
			}else{
				P_a=str_a;
				offset_a=0;
			}
			if(k_msgq_put(&uart_msgq2,&P_a,K_NO_WAIT)!=0)
			{
			//丢弃
			printk("too much\n");
			}
			P_a=NULL;
		}
	}
	return 0;
}
```

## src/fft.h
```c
/**
 * @file         fft.h
 * @details      用于定义FFT
 * @author       jjl
 */
#ifndef _FFT_H
#define _FFT_H
/*
===========================
头文件包括
===========================
*/
#include <zephyr/kernel.h>
#include <zephyr/logging/log.h>
#include <zephyr/drivers/gpio.h>
#include "nrfx_timer.h"
#include <nrfx_gpiote.h>
#include <arm_math.h>
#include <arm_const_structs.h>
#include "uart.h"
#include "mymacros.h"
#include <stdio.h>
#include <string.h>
// #include <support_functions.h>
/*
===========================
宏定义包括
===========================
*/

/* FFT长度 */
#define FFT_LENGTH 1024
// #define FFT_LENGTH 2048
extern struct k_msgq uart_msgq2;
/*
===========================
函数申明包括
===========================
*/
/**
 * @brief        fft运作
 */
int fft(void);
#endif
```

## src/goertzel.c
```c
#include <math.h>
#include "goertzel.h"



float goertzel(int *data, int N, float fs, float f_target) {
    int k = (int)(0.5f + ((N * f_target) / fs));
    float omega = (2.0f * PI * k) / N;
    float coeff = 2.0f * cosf(omega);

    float s_prev = 0.0f;
    float s_prev2 = 0.0f;
    float s;
	// printk("da:%d\n",(int)data[0]);
	// printk("da:%d\n",(int)data[1]);
	// printk("da:%d\n",(int)data[2]);
	// printk("da:%d\n",(int)data[3]);
	// printk("da:%d\n",(int)data[4]);
	// printk("da:%d\n",(int)data[5]);
    for (int n = 0; n < N; n++) {
        s = data[n] + coeff * s_prev - s_prev2;
        s_prev2 = s_prev;
        s_prev = s;
    }

    return s_prev2 * s_prev2 + s_prev * s_prev - coeff * s_prev * s_prev2;
}
```

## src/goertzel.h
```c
#ifndef GOERTZEL_H
#define GOERTZEL_H
#define PI 3.14159265358979f
float goertzel(int *data, int N, float fs, float f_target);

#endif
```

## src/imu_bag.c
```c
/*
 * Copyright (c) 2012-2014 Wind River Systems, Inc.
 *
 * SPDX-License-Identifier: Apache-2.0
 */

#include "imu_bag.h"
#include "mymacros.h"
uint8_t data[15];
uint8_t icm42688_data[15];
uint8_t lis3dml_data[15];

uint32_t icm42688_timestamp = 0;

int16_t acc_data[3] = {0};
int16_t gyro_data[3] = {0};
int16_t mag_data[3] = {0};
//处理过的时间戳
int icm42688_time= 0;
/**
 * @brief Read a sequence of bytes from a sensor registers 重新封装IIC的读取
 * 
 */
void sensor_register_read(uint8_t sensor_addr, uint8_t reg_addr, uint8_t *data, uint8_t len)
{
	EspI2cReadBytes(sensor_addr, reg_addr, data, len);
}
/**
 * @brief Write a byte to a sensor register 重新封装IIC的写入
 */
void sensor_register_write_byte(uint8_t sensor_addr, uint8_t reg_addr, uint8_t data)
{
	EspI2cWriteByte(sensor_addr, reg_addr, data);
}
/**
 * @brief icm (imu) 初始化写入命令
 */
void icm_init()
{
	sensor_register_write_byte(ICM_I2C_ADDR, ICM_BANK_SEL, 0);
	k_msleep(10);
	/* 读WHO_AM_I寄存器 */
	sensor_register_read(ICM_I2C_ADDR, ICM_WHO_AM_I, data, 1);
	printk("icm42688 read id:%X\n", data[0]);
	if (data[0] == ICM_ID)
	{
		printk("icm42688 ready!\n");
	}
	else
	{
		printk("icm42688 not found!\n");
	}
	/* 配置寄存器 */
	sensor_register_write_byte(ICM_I2C_ADDR, ICM_DEVICE_CONFIG, 0x01); // 软重启
	k_msleep(10);													   // 等待10ms

	sensor_register_write_byte(ICM_I2C_ADDR, ICM_POWER_MAG, 0x1F); // 开启陀螺仪和加速度计
	k_msleep(100);

	/* 配置FS和ODR */
	// sensor_register_write_byte(ICM_I2C_ADDR, ICM_GYRO_CONFIG0, 0x67); // 250dps,200Hz
	sensor_register_write_byte(ICM_I2C_ADDR, ICM_GYRO_CONFIG0, 0x66); // 250dps,1000Hz
	k_msleep(50);
	// sensor_register_write_byte(ICM_I2C_ADDR, ICM_ACCEL_CONFIG0, 0x47); // 4g, 100Hz（这里应为200Hz）
	sensor_register_write_byte(ICM_I2C_ADDR, ICM_ACCEL_CONFIG0, 0x46); // 4g, 1000Hz
	k_msleep(50);
	sensor_register_write_byte(ICM_I2C_ADDR, ICM_GYRO_ACCEL_CONFIG0, 0x55); // 20Hz BW,这里根据配置而变化
	k_msleep(50);
	printk("icm42688 gyr and acc config finished!");

	/* 开启时间戳 */
	sensor_register_write_byte(ICM_I2C_ADDR, ICM_TMST_CONFIG, 0x33);
	k_msleep(50);
}
/**
 * @brief lis3dml (bag) 初始化写入命令
 */
void lis3dml_init()
{
	/* 读WHO_AM_I寄存器 */
	sensor_register_read(LIS3MDL_I2C_ADDR_G, LIS3MDL_WHO_AM_I, data, 1);
	printk("lis3dml read id:%d\n", data[0]);
	if (data[0] == LIS3MDL_ID)
	{
		printk("lis3dml ready!");
	}
	else
	{
		printk("lis3dml not found!");
	}
	/* 软重启 */
	sensor_register_write_byte(LIS3MDL_I2C_ADDR_G, LIS3MDL_CTRL_REG2, 0x04);//重启选项
	/* 延时 */
	k_msleep(50);
	/* 配置BDU */
	sensor_register_write_byte(LIS3MDL_I2C_ADDR_G, LIS3MDL_CTRL_REG5, 0x40);//不更新数据直到完成数据被读取
	/* 延时 */
	k_msleep(50);
	/* 配置 */
	// sensor_register_write_byte(LIS3MDL_I2C_ADDR_G, LIS3MDL_CTRL_REG1, 0x60 | 0x1C); // X、Y轴high performance，80Hz(这个不太对应该是ultra-high-perfermance)
	sensor_register_write_byte(LIS3MDL_I2C_ADDR_G, LIS3MDL_CTRL_REG1, 0x40 | 0x02); // X、Y轴high performance，300Hz(只支持high-perfermance)
	sensor_register_write_byte(LIS3MDL_I2C_ADDR_G, LIS3MDL_CTRL_REG2, 0x00);		// ±4 gauss
	sensor_register_write_byte(LIS3MDL_I2C_ADDR_G, LIS3MDL_CTRL_REG3, 0x00);		// 连续转换模式
	sensor_register_write_byte(LIS3MDL_I2C_ADDR_G, LIS3MDL_CTRL_REG4, 0x0C);		// Z轴high performance(这个不太对应该是ultra-high-perfermance)
}
/**
 * @brief imu与bag 初始化程序
 */
 void imu_bag_init(void)
{
	I2cInit();
	/* 初始化icm42688 */
	icm_init();
	// /* 初始化lis3dml */
	lis3dml_init();
}
/**
 * @brief imu与bag 读取程序
 */
void imu_bag_read_data( void)
{
	//创建一个
		//用于存储格式化字符串
		char str_42688[100];
		char str_3dml[100];
		// 字符指针
		char *ptr_42688;
		char *ptr_3dml;
		/* ICM-42688-P 读数据 */
		sensor_register_write_byte(ICM_I2C_ADDR, ICM_BANK_SEL, 0);
		sensor_register_write_byte(ICM_I2C_ADDR, ICM_SIGNAL_PATH_RESET, 0x04);
		sensor_register_read(ICM_I2C_ADDR, ICM_ACCEL_DATA_X1, icm42688_data, 12);
		sensor_register_write_byte(ICM_I2C_ADDR, ICM_BANK_SEL, 1);
		sensor_register_read(ICM_I2C_ADDR, ICM_TMSTVAL0, icm42688_data + 12, 3);

		/* LIS3DML读数据 */
		sensor_register_read(LIS3MDL_I2C_ADDR_G, LIS3MDL_OUT_X_L, lis3dml_data, 6);
		
		//进行时间戳处理
		icm42688_timestamp = (icm42688_data[14] << 16) + (icm42688_data[13] << 8) + icm42688_data[12];
		icm42688_time=icm42688_timestamp/1000;

		if(IMU_UART_Display)
		{
			/* ICM42688打印数据 */
			acc_data[0] = (icm42688_data[0] << 8) + icm42688_data[1];
			acc_data[1] = (icm42688_data[2] << 8) + icm42688_data[3];
			acc_data[2] = (icm42688_data[4] << 8) + icm42688_data[5];
			gyro_data[0] = (icm42688_data[6] << 8) + icm42688_data[7];
			gyro_data[1] = (icm42688_data[8] << 8) + icm42688_data[9];
			gyro_data[2] = (icm42688_data[10] << 8) + icm42688_data[11];
			icm42688_timestamp = (icm42688_data[14] << 16) + (icm42688_data[13] << 8) + icm42688_data[12];
			// /* LIS3DML打印数据 */
			mag_data[0] = lis3dml_data[0] + (lis3dml_data[1] << 8);
			mag_data[1] = lis3dml_data[2] + (lis3dml_data[3] << 8);
			mag_data[2] = lis3dml_data[4] + (lis3dml_data[5] << 8);
			// 将上面两行数据直接用串口打印
			// 将整数格式化成指针
			sprintf(str_42688,"icm42688,acc_x:%d,acc_y:%d,acc_z:%d,gyr_x:%d,gyr_y:%d,gyr_z:%d,tick:%ld\n",acc_data[0], acc_data[1], acc_data[2],
				gyro_data[0], gyro_data[1], gyro_data[2],(long int)icm42688_timestamp);
			ptr_42688 = str_42688;
			sprintf(str_3dml,"lis3dml,mag_x:%d,mag_y:%d,mag_z:%d\n",
					mag_data[0], mag_data[1], mag_data[2]);
			ptr_3dml = str_3dml;
			//进行数据队列的填充
			//用于将数据添加进去队列
			if(k_msgq_put(&uart_msgq3,&ptr_42688,K_NO_WAIT)!=0)
			{
				//丢弃
				printk("too much\n");
			}
			if(k_msgq_put(&uart_msgq3,&ptr_3dml,K_NO_WAIT)!=0)
			{
				//丢弃
				printk("too much\n");
			}
			// print_uart(ptr_42688);
			// print_uart(ptr_3dml);
			memset(str_42688,0,sizeof(str_42688));
			memset(str_3dml,0,sizeof(str_3dml));
		}


}
```

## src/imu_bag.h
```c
/**
 * @file         imu_bag.h
 * @details      用于定义imu与bag联合程序
 * @author       jjl
 */
#ifndef _IMU_BAG_H
#define _IMU_BAG_H

/*
===========================
头文件包括
===========================
*/
#include <stdio.h>
#include <zephyr/kernel.h>
#include <zephyr/drivers/gpio.h>
#include <nrfx_gpiote.h>
#include "soft_iic.h"
#include "icm_42688.h"
#include "lis3dml.h"
#include "uart.h"
/*
===========================
宏定义
===========================
*/
/* 1000 msec = 1 sec */
#define SLEEP_TIME_MS 1000
/*
===========================
变量声明
===========================
*/
extern uint8_t icm42688_data[15];
extern uint8_t lis3dml_data[15];
extern int16_t acc_data[3];
extern int16_t gyro_data[3];
extern int16_t mag_data[3];
extern uint32_t icm42688_timestamp;

//声明消息队列
extern struct k_msgq uart_msgq2;
extern struct k_msgq uart_msgq3;
/*
===========================
函数声明
===========================
*/
/**
 * @brief icm (imu) 初始化写入命令
 */
void icm_init();
/**
 * @brief lis3dml (bag) 初始化写入命令
 */
void lis3dml_init();
/**
 * @brief read bytes to a sensor register 重新封装IIC的读取
 */
void sensor_register_read(uint8_t sensor_addr, uint8_t reg_addr, uint8_t *data, uint8_t len);
/**
 * @brief Write a byte to a sensor register 重新封装IIC的写入
 */
void sensor_register_write_byte(uint8_t sensor_addr, uint8_t reg_addr, uint8_t data);
/**
 * @brief imu与bag 初始化程序
 */
void imu_bag_init(void);
/**
 * @brief imu与bag 读取程序
 */
void imu_bag_read_data(void);

#endif
```

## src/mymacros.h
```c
// my_macros.h
#ifndef MY_MACROS_H
#define MY_MACROS_H
//调试的一个宏定义,True则显示PD,反之亦然
// #define  PD_UART_Display true 
#define  PD_UART_Display false 

//调试的一个宏定义,True则显示IMU,反之亦然
// #define  IMU_UART_Display true 
#define  IMU_UART_Display false 

//调试的一个宏定义,True则显示FFT(所有),反之亦然
// #define  FFT_UART_Display true 
#define  FFT_UART_Display false 

//调试的一个宏定义,True则显示FFT(六个频率),反之亦然
#define  fft_UART_Display true 
// #define  fft_UART_Display false 

//调试的一个宏定义,True则显示1000个PD数据,反之亦然
// #define  fft_pd_uart true 
#define  fft_pd_uart false 

//切换两种ad
// #define AD_1220 true
#define AD_1220 false

#define AD_32  true
// #define AD_32  false

//是否进行蓝牙开始
#define BLE_OK  true
// #define BLE_OK  false

#endif
```
